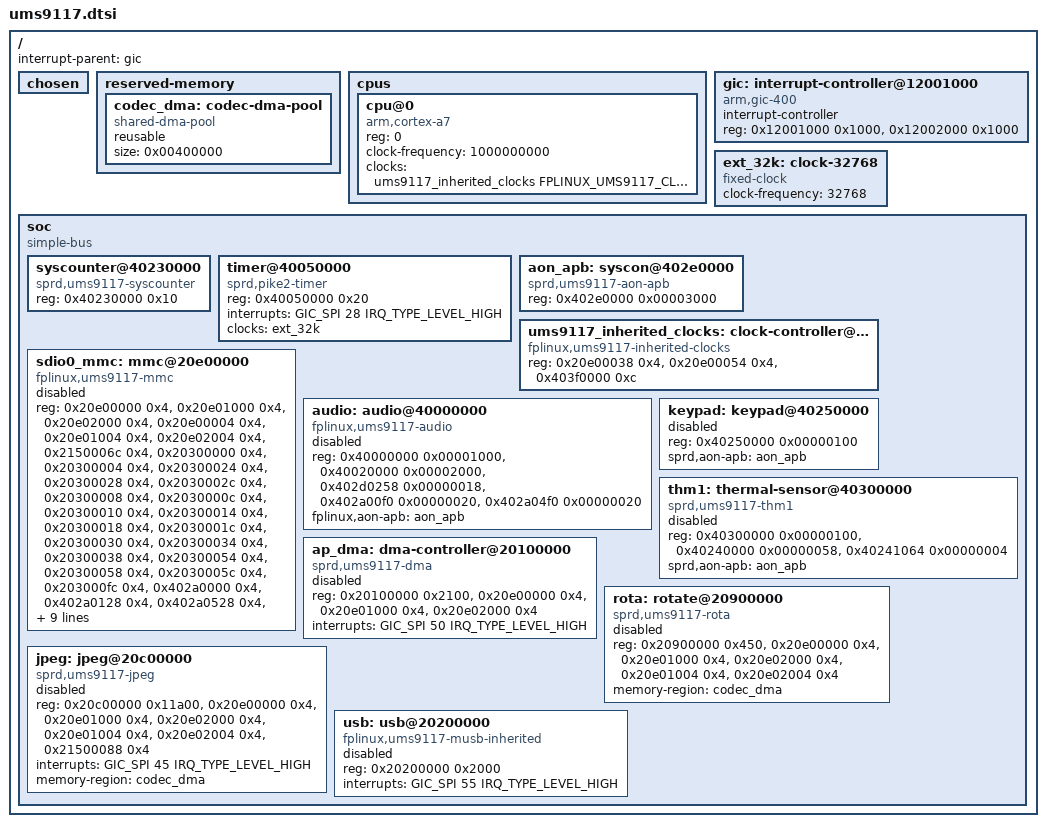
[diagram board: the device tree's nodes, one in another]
// SPDX-License-Identifier: GPL-2.0-only
#include <dt-bindings/clock/fplinux,ums9117-inherited-clk.h>
#include <dt-bindings/interrupt-controller/arm-gic.h>

/ {
	#address-cells = <1>;
	#size-cells = <1>;
	interrupt-parent = <&gic>;

	chosen {
#include "fplinux-root.dtsi"
	};

	reserved-memory {
		#address-cells = <1>;
		#size-cells = <1>;
		ranges;

		/*
		 * JPEG and ROTA need physically contiguous DMA buffers. Sharing
		 * one reusable CMA pool avoids a second reservation and leaves
		 * unused pages available for movable allocations.
		 */
		codec_dma: codec-dma-pool {
			compatible = "shared-dma-pool";
			reusable;
			size = <0x00400000>;
		};
	};

	cpus {
		#address-cells = <1>;
		#size-cells = <0>;

		cpu@0 {
			device_type = "cpu";
			compatible = "arm,cortex-a7";
			reg = <0>;
			clock-frequency = <1000000000>;
			clocks = <&ums9117_inherited_clocks
				  FPLINUX_UMS9117_CLK_CA7_CORE>;
		};
	};

	gic: interrupt-controller@12001000 {
		compatible = "arm,gic-400";
		#interrupt-cells = <3>;
		#address-cells = <0>;
		interrupt-controller;
		reg = <0x12001000 0x1000>,
		      <0x12002000 0x1000>;
	};

	ext_32k: clock-32768 {
		compatible = "fixed-clock";
		#clock-cells = <0>;
		clock-frequency = <32768>;
	};

	soc {
		compatible = "simple-bus";
		#address-cells = <1>;
		#size-cells = <1>;
		ranges;

		syscounter@40230000 {
			compatible = "sprd,ums9117-syscounter";
			reg = <0x40230000 0x10>;
		};

		timer@40050000 {
			compatible = "sprd,pike2-timer";
			reg = <0x40050000 0x20>;
			interrupts = <GIC_SPI 28 IRQ_TYPE_LEVEL_HIGH>;
			clocks = <&ext_32k>;
		};

		aon_apb: syscon@402e0000 {
			compatible = "sprd,ums9117-aon-apb", "syscon";
			reg = <0x402e0000 0x00003000>;
		};

		ums9117_inherited_clocks: clock-controller@20e00038 {
			compatible = "fplinux,ums9117-inherited-clocks";
			reg = <0x20e00038 0x4>,
			      <0x20e00054 0x4>,
			      <0x403f0000 0xc>;
			reg-names = "ca7-divider", "ca7-source", "mpll";
			#clock-cells = <1>;
		};

		sdio0_mmc: mmc@20e00000 {
			compatible = "fplinux,ums9117-mmc";
			reg = <0x20e00000 0x4>, <0x20e01000 0x4>, <0x20e02000 0x4>,
			      <0x20e00004 0x4>, <0x20e01004 0x4>, <0x20e02004 0x4>,
			      <0x2150006c 0x4>,
			      <0x20300000 0x4>, <0x20300004 0x4>, <0x20300024 0x4>,
			      <0x20300028 0x4>, <0x2030002c 0x4>, <0x20300008 0x4>,
			      <0x2030000c 0x4>, <0x20300010 0x4>, <0x20300014 0x4>,
			      <0x20300018 0x4>, <0x2030001c 0x4>, <0x20300030 0x4>,
			      <0x20300034 0x4>, <0x20300038 0x4>, <0x20300054 0x4>,
			      <0x20300058 0x4>, <0x2030005c 0x4>, <0x203000fc 0x4>,
			      <0x402a0000 0x4>,
			      <0x402a0128 0x4>, <0x402a0528 0x4>, <0x402a012c 0x4>,
			      <0x402a052c 0x4>, <0x402a0134 0x4>, <0x402a0534 0x4>,
			      <0x402a0120 0x4>, <0x402a0520 0x4>, <0x402a0124 0x4>,
			      <0x402a0524 0x4>, <0x402a0130 0x4>, <0x402a0530 0x4>,
			      /* ADI access is serialized through the hardware user lock. */
			      <0x40600000 0x400>, <0x40608000 0x1000>,
			      <0x2030003c 0x4>,
			      <0x402c0000 0x4>, <0x402c0004 0x4>;
			reg-names = "gate-state", "gate-set", "gate-clear",
				    "ap-reset-state", "ap-reset-set", "ap-reset-clear",
				    "ap-clock-selector", "block-count", "block-size",
				    "present-state", "host-control1",
				    "clock-timeout-reset", "argument",
				    "transfer-command", "response0", "response1",
				    "response2", "response3", "interrupt-status",
				    "interrupt-status-enable", "interrupt-signal-enable",
				    "adma-error", "adma2-address-low",
				    "adma2-address-high", "host-version-slot-int",
				    "pwr-pad-ctl", "cmd-mux", "cmd-pad", "d0-mux",
				    "d0-pad", "clk-mux", "clk-pad", "d3-mux", "d3-pad",
				    "d2-mux", "d2-pad", "d1-mux", "d1-pad",
				    "adi-controller", "analog-slave",
				    "host-control2", "card-detect-data",
				    "card-detect-mask";
			interrupts = <GIC_SPI 57 IRQ_TYPE_LEVEL_HIGH>;
			status = "disabled";
		};

		audio: audio@40000000 {
			compatible = "fplinux,ums9117-audio";
			reg = <0x40000000 0x00001000>,
			      <0x40020000 0x00002000>,
			      <0x402d0258 0x00000018>,
			      <0x402a00f0 0x00000020>,
			      <0x402a04f0 0x00000020>;
			reg-names = "aud", "vbc", "clk1", "pinmux", "pinconf";
			fplinux,aon-apb = <&aon_apb>;
			status = "disabled";
		};

		keypad: keypad@40250000 {
			reg = <0x40250000 0x00000100>;
			sprd,aon-apb = <&aon_apb>;
			status = "disabled";
		};

		thm1: thermal-sensor@40300000 {
			compatible = "sprd,ums9117-thm1";
			reg = <0x40300000 0x00000100>,
			      <0x40240000 0x00000058>,
			      <0x40241064 0x00000004>;
			reg-names = "thm", "efuse-control", "efuse-block25";
			sprd,aon-apb = <&aon_apb>;
			status = "disabled";
		};

		ap_dma: dma-controller@20100000 {
			compatible = "sprd,ums9117-dma";
			#dma-cells = <1>;
			reg = <0x20100000 0x2100>,
			      <0x20e00000 0x4>,
			      <0x20e01000 0x4>,
			      <0x20e02000 0x4>;
			reg-names = "dma", "ap-ahb-state", "ap-ahb-set", "ap-ahb-clear";
			interrupts = <GIC_SPI 50 IRQ_TYPE_LEVEL_HIGH>;
			status = "disabled";
		};

		rota: rotate@20900000 {
			compatible = "sprd,ums9117-rota";
			reg = <0x20900000 0x450>,
			      <0x20e00000 0x4>,
			      <0x20e01000 0x4>,
			      <0x20e02000 0x4>,
			      <0x20e01004 0x4>,
			      <0x20e02004 0x4>;
			reg-names = "rota", "ap-ahb-gate-state", "ap-ahb-gate-set",
				    "ap-ahb-gate-clear", "ap-ahb-reset-set",
				    "ap-ahb-reset-clear";
			memory-region = <&codec_dma>;
			status = "disabled";
		};

		jpeg: jpeg@20c00000 {
			compatible = "sprd,ums9117-jpeg";
			reg = <0x20c00000 0x11a00>,
			      <0x20e00000 0x4>,
			      <0x20e01000 0x4>,
			      <0x20e02000 0x4>,
			      <0x20e01004 0x4>,
			      <0x20e02004 0x4>,
			      <0x21500088 0x4>;
			reg-names = "jpeg", "ap-ahb-gate-state", "ap-ahb-gate-set",
				    "ap-ahb-gate-clear", "ap-ahb-reset-set",
				    "ap-ahb-reset-clear", "dcam-clock";
			interrupts = <GIC_SPI 45 IRQ_TYPE_LEVEL_HIGH>;
			memory-region = <&codec_dma>;
			status = "disabled";
		};

		usb: usb@20200000 {
			compatible = "fplinux,ums9117-musb-inherited";
			reg = <0x20200000 0x2000>;
			interrupts = <GIC_SPI 55 IRQ_TYPE_LEVEL_HIGH>;
			status = "disabled";
		};
	};
};
